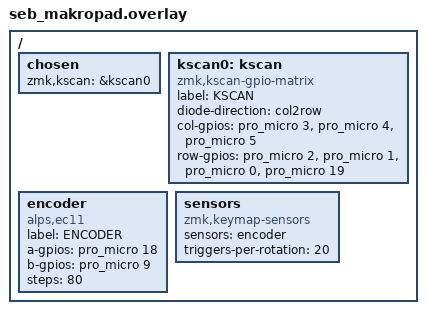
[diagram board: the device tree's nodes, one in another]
/ {
    chosen {
        zmk,kscan = &kscan0;
    };

    kscan0: kscan {
        compatible = "zmk,kscan-gpio-matrix";
        label = "KSCAN";
        diode-direction = "col2row";

        col-gpios
            = <&pro_micro 3 GPIO_ACTIVE_HIGH> // Pin 6 (col0)
            , <&pro_micro 4 GPIO_ACTIVE_HIGH> // Pin 7 (col1)
            , <&pro_micro 5 GPIO_ACTIVE_HIGH> // Pin 8 (col2)
            ;

        row-gpios
            = <&pro_micro 2 (GPIO_ACTIVE_HIGH | GPIO_PULL_DOWN)>  // Pin 5 (row0)
            , <&pro_micro 1 (GPIO_ACTIVE_HIGH | GPIO_PULL_DOWN)>  // Pin 2 (row1)
            , <&pro_micro 0 (GPIO_ACTIVE_HIGH | GPIO_PULL_DOWN)>  // Pin 1 (row2)
            , <&pro_micro 19 (GPIO_ACTIVE_HIGH | GPIO_PULL_DOWN)> // Pin 22 (Button S1)
            ;
    };

    encoder: encoder {
        compatible = "alps,ec11";
        label = "ENCODER";
        a-gpios = <&pro_micro 18 (GPIO_ACTIVE_HIGH | GPIO_PULL_UP)>; // Pin 21 (A)
        b-gpios = <&pro_micro 9 (GPIO_ACTIVE_HIGH | GPIO_PULL_UP)>;  // Pin 12 (B)
        steps = <80>;
    };

    sensors {
        compatible = "zmk,keymap-sensors";
        sensors = <&encoder>;
        triggers-per-rotation = <20>;
    };
};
